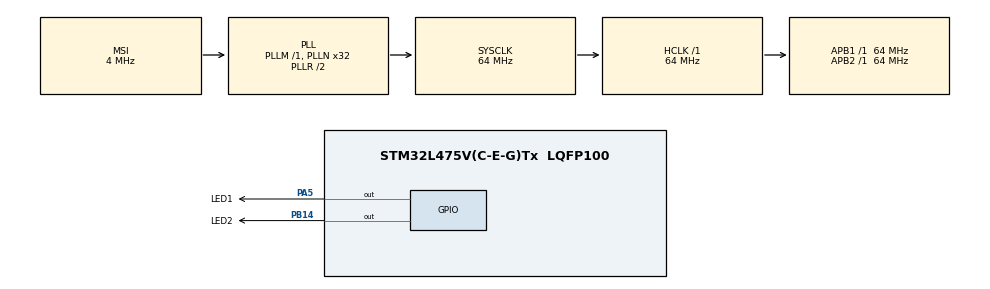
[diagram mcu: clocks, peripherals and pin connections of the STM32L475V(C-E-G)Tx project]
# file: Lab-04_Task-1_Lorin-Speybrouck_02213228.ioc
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Mcu.Family=STM32L4
Mcu.Name=STM32L475V(C-E-G)Tx
Mcu.Package=LQFP100
NVIC.PriorityGroup=NVIC_PRIORITYGROUP_4
PA5.GPIO_Label=LED1
PA5.PinState=GPIO_PIN_RESET
PA5.Signal=GPIO_Output
PB14.GPIO_Label=LED2
PB14.Signal=GPIO_Output
ProjectManager.HeapSize=0x200
ProjectManager.StackSize=0x400
ProjectManager.TargetToolchain=STM32CubeIDE
RCC.ADCFreq_Value=48000000
RCC.AHBFreq_Value=64000000
RCC.APB1Freq_Value=64000000
RCC.APB1TimFreq_Value=64000000
RCC.APB2Freq_Value=64000000
RCC.APB2TimFreq_Value=64000000
RCC.CortexFreq_Value=64000000
RCC.HCLKFreq_Value=64000000
RCC.HSE_VALUE=8000000
RCC.HSI_VALUE=16000000
RCC.LSE_VALUE=32768
RCC.MSI_VALUE=4000000
RCC.PLLN=32
RCC.PLLSAI1N=24
RCC.SYSCLKFreq_VALUE=64000000
RCC.SYSCLKSource=RCC_SYSCLKSOURCE_PLLCLK
RCC.USBFreq_Value=48000000
RCC.VCOOutputFreq_Value=128000000
TIM2.AutoReloadPreload=TIM_AUTORELOAD_PRELOAD_ENABLE
TIM2.Period=499
TIM2.Prescaler=63999
VP_TIM2_VS_ClockSourceINT.Mode=Internal
board=B-L475E-IOT01A1

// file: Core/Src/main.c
/* USER CODE BEGIN Header */
/**
 ******************************************************************************
 * @file           : main.c
 * @brief          : Main program body
 ******************************************************************************
 * @attention
 *
 * Copyright (c) 2024 STMicroelectronics.
 * All rights reserved.
 *
 * This software is licensed under terms that can be found in the LICENSE file
 * in the root directory of this software component.
 * If no LICENSE file comes with this software, it is provided AS-IS.
 *
 ******************************************************************************
 */
/* USER CODE END Header */
#include "main.h"

TIM_HandleTypeDef htim2;

void SystemClock_Config(void);
static void MX_GPIO_Init(void);
static void MX_TIM2_Init(void);

int main(void) {

	/* MCU Configuration--------------------------------------------------------*/

	/* Reset of all peripherals, Initializes the Flash interface and the Systick. */
	HAL_Init();

	/* Configure the system clock */
	SystemClock_Config();

	/* Initialize all configured peripherals */
	MX_GPIO_Init();
	MX_TIM2_Init();
	/* USER CODE BEGIN 2 */
	HAL_TIM_Base_Start(&htim2);
	/* USER CODE END 2 */

	/* Infinite loop */
	while (1) {

		/* USER CODE BEGIN 3 */
		if (__HAL_TIM_GET_COUNTER(&htim2) == 150) {
			HAL_GPIO_WritePin(GPIOA, LED1_Pin, GPIO_PIN_SET);
			HAL_GPIO_WritePin(GPIOB, LED2_Pin, GPIO_PIN_SET);
		}
		if (__HAL_TIM_GET_COUNTER(&htim2) == 399) {
			HAL_GPIO_WritePin(GPIOA, LED1_Pin, GPIO_PIN_RESET);
			HAL_GPIO_WritePin(GPIOB, LED2_Pin, GPIO_PIN_RESET);
		}
	}
	/* USER CODE END 3 */
}

void SystemClock_Config(void) {
	RCC_OscInitTypeDef RCC_OscInitStruct = { 0 };
	RCC_ClkInitTypeDef RCC_ClkInitStruct = { 0 };

	/** Configure the main internal regulator output voltage
	 */
	if (HAL_PWREx_ControlVoltageScaling(PWR_REGULATOR_VOLTAGE_SCALE1)
			!= HAL_OK) {
		Error_Handler();
	}

	/** Initializes the RCC Oscillators according to the specified parameters
	 * in the RCC_OscInitTypeDef structure.
	 */
	RCC_OscInitStruct.OscillatorType = RCC_OSCILLATORTYPE_MSI;
	RCC_OscInitStruct.MSIState = RCC_MSI_ON;
	RCC_OscInitStruct.MSICalibrationValue = 0;
	RCC_OscInitStruct.MSIClockRange = RCC_MSIRANGE_6;
	RCC_OscInitStruct.PLL.PLLState = RCC_PLL_ON;
	RCC_OscInitStruct.PLL.PLLSource = RCC_PLLSOURCE_MSI;
	RCC_OscInitStruct.PLL.PLLM = 1;
	RCC_OscInitStruct.PLL.PLLN = 32;
	RCC_OscInitStruct.PLL.PLLP = RCC_PLLP_DIV7;
	RCC_OscInitStruct.PLL.PLLQ = RCC_PLLQ_DIV2;
	RCC_OscInitStruct.PLL.PLLR = RCC_PLLR_DIV2;
	if (HAL_RCC_OscConfig(&RCC_OscInitStruct) != HAL_OK) {
		Error_Handler();
	}

	/** Initializes the CPU, AHB and APB buses clocks
	 */
	RCC_ClkInitStruct.ClockType = RCC_CLOCKTYPE_HCLK | RCC_CLOCKTYPE_SYSCLK
			| RCC_CLOCKTYPE_PCLK1 | RCC_CLOCKTYPE_PCLK2;
	RCC_ClkInitStruct.SYSCLKSource = RCC_SYSCLKSOURCE_PLLCLK;
	RCC_ClkInitStruct.AHBCLKDivider = RCC_SYSCLK_DIV1;
	RCC_ClkInitStruct.APB1CLKDivider = RCC_HCLK_DIV1;
	RCC_ClkInitStruct.APB2CLKDivider = RCC_HCLK_DIV1;

	if (HAL_RCC_ClockConfig(&RCC_ClkInitStruct, FLASH_LATENCY_3) != HAL_OK) {
		Error_Handler();
	}
}

static void MX_TIM2_Init(void) {

	TIM_ClockConfigTypeDef sClockSourceConfig = { 0 };
	TIM_MasterConfigTypeDef sMasterConfig = { 0 };

	htim2.Instance = TIM2;
	htim2.Init.Prescaler = 63999;
	htim2.Init.CounterMode = TIM_COUNTERMODE_UP;
	htim2.Init.Period = 499;
	htim2.Init.ClockDivision = TIM_CLOCKDIVISION_DIV1;
	htim2.Init.AutoReloadPreload = TIM_AUTORELOAD_PRELOAD_ENABLE;
	if (HAL_TIM_Base_Init(&htim2) != HAL_OK) {
		Error_Handler();
	}
	sClockSourceConfig.ClockSource = TIM_CLOCKSOURCE_INTERNAL;
	if (HAL_TIM_ConfigClockSource(&htim2, &sClockSourceConfig) != HAL_OK) {
		Error_Handler();
	}
	sMasterConfig.MasterOutputTrigger = TIM_TRGO_RESET;
	sMasterConfig.MasterSlaveMode = TIM_MASTERSLAVEMODE_DISABLE;
	if (HAL_TIMEx_MasterConfigSynchronization(&htim2, &sMasterConfig)
			!= HAL_OK) {
		Error_Handler();
	}

}

static void MX_GPIO_Init(void) {
	GPIO_InitTypeDef GPIO_InitStruct = { 0 };

	/* GPIO Ports Clock Enable */
	__HAL_RCC_GPIOA_CLK_ENABLE();
	__HAL_RCC_GPIOB_CLK_ENABLE();

	/*Configure GPIO pin Output Level */
	HAL_GPIO_WritePin(LED1_GPIO_Port, LED1_Pin, GPIO_PIN_RESET);

	/*Configure GPIO pin Output Level */
	HAL_GPIO_WritePin(LED2_GPIO_Port, LED2_Pin, GPIO_PIN_RESET);

	/*Configure GPIO pin : LED1_Pin */
	GPIO_InitStruct.Pin = LED1_Pin;
	GPIO_InitStruct.Mode = GPIO_MODE_OUTPUT_PP;
	GPIO_InitStruct.Pull = GPIO_NOPULL;
	GPIO_InitStruct.Speed = GPIO_SPEED_FREQ_LOW;
	HAL_GPIO_Init(LED1_GPIO_Port, &GPIO_InitStruct);

	/*Configure GPIO pin : LED2_Pin */
	GPIO_InitStruct.Pin = LED2_Pin;
	GPIO_InitStruct.Mode = GPIO_MODE_OUTPUT_PP;
	GPIO_InitStruct.Pull = GPIO_NOPULL;
	GPIO_InitStruct.Speed = GPIO_SPEED_FREQ_LOW;
	HAL_GPIO_Init(LED2_GPIO_Port, &GPIO_InitStruct);

}

void Error_Handler(void) {
	__disable_irq();
	while (1) {
	}
}
